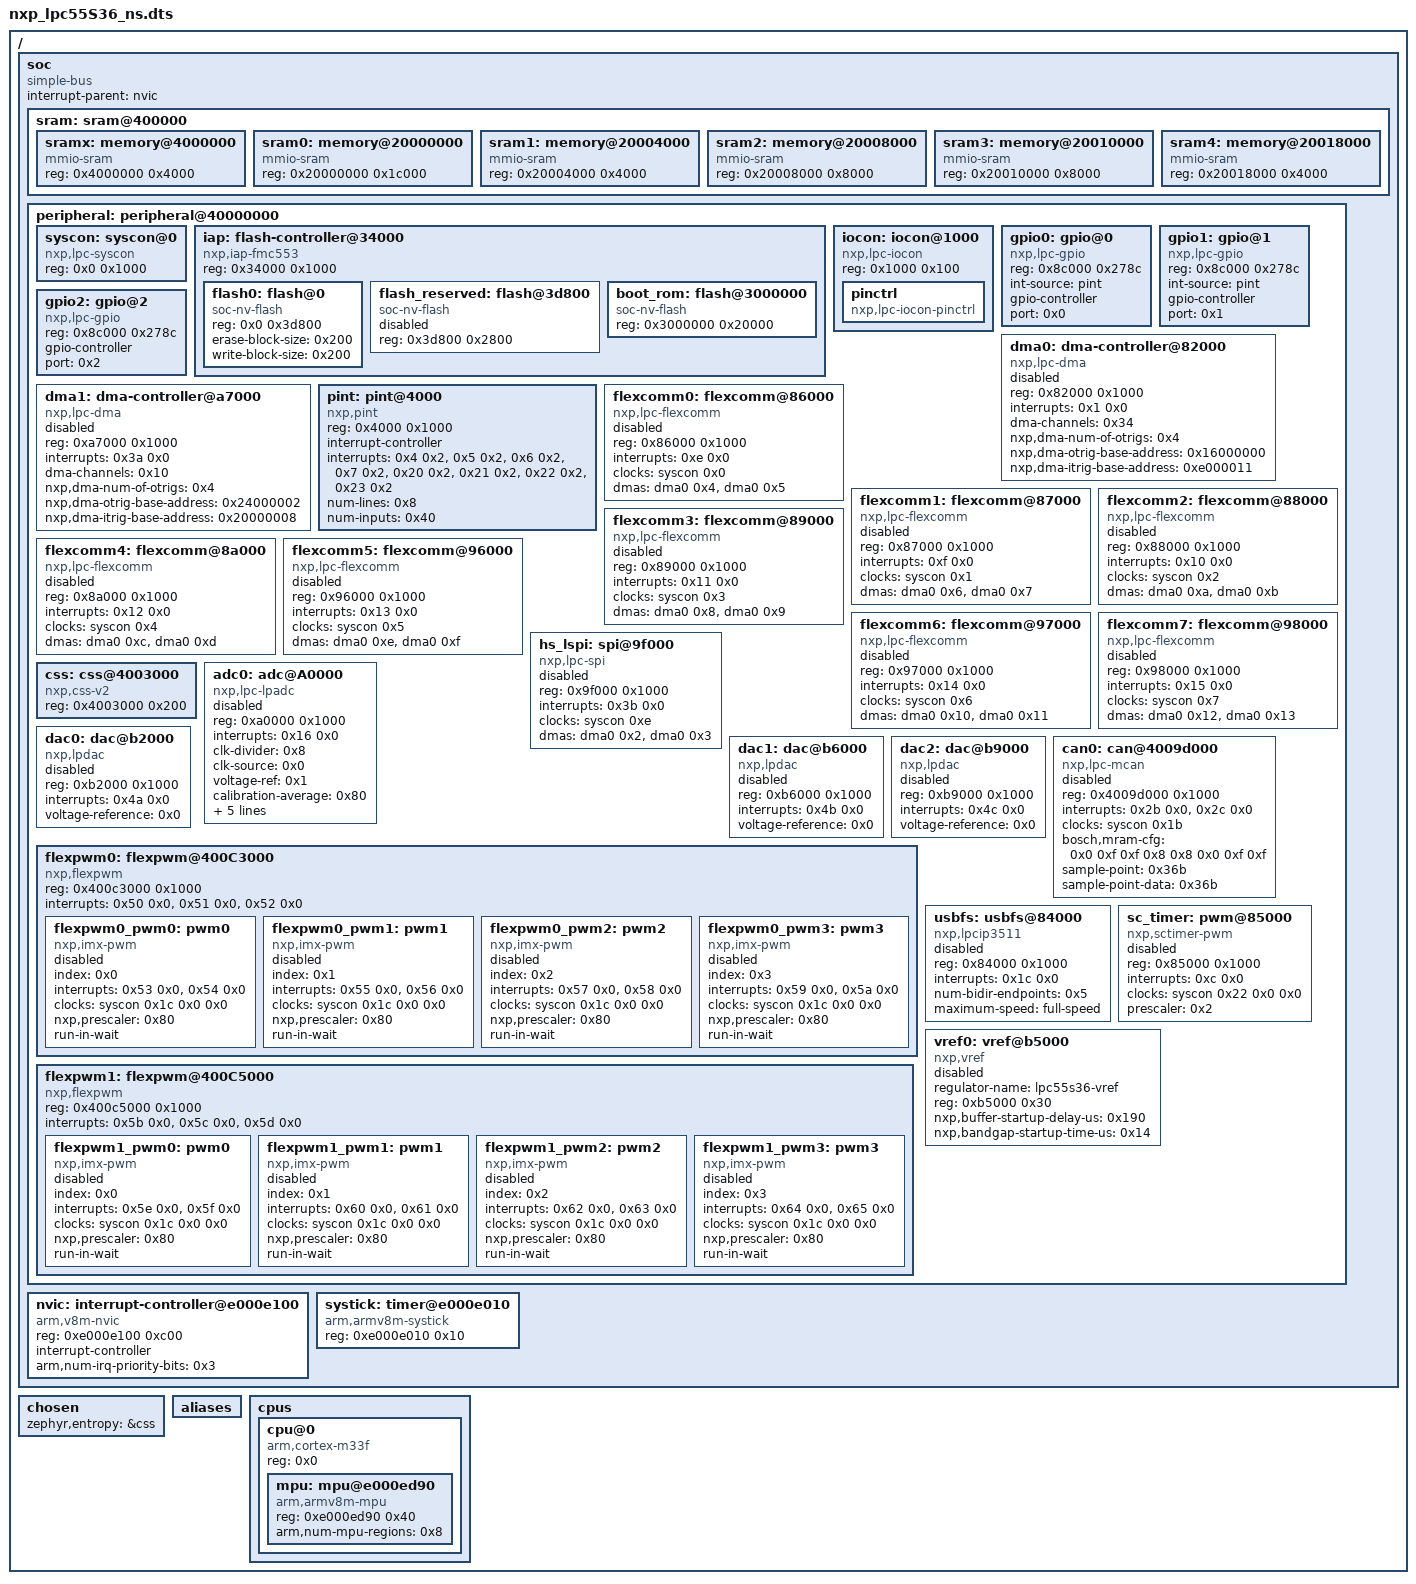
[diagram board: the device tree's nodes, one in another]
/dts-v1/;

/ {
	#address-cells = < 0x1 >;
	#size-cells = < 0x1 >;
	soc {
		#address-cells = < 0x1 >;
		#size-cells = < 0x1 >;
		compatible = "simple-bus";
		interrupt-parent = < &nvic >;
		ranges;
		sram: sram@400000 {
			ranges = < 0x4000000 0x4000000 0x20000000 >;
			#address-cells = < 0x1 >;
			#size-cells = < 0x1 >;
			sramx: memory@4000000 {
				compatible = "mmio-sram";
				reg = < 0x4000000 0x4000 >;
			};
			sram0: memory@20000000 {
				compatible = "mmio-sram";
				reg = < 0x20000000 0x1c000 >;
			};
			sram1: memory@20004000 {
				compatible = "mmio-sram";
				reg = < 0x20004000 0x4000 >;
			};
			sram2: memory@20008000 {
				compatible = "mmio-sram";
				reg = < 0x20008000 0x8000 >;
			};
			sram3: memory@20010000 {
				compatible = "mmio-sram";
				reg = < 0x20010000 0x8000 >;
			};
			sram4: memory@20018000 {
				compatible = "mmio-sram";
				reg = < 0x20018000 0x4000 >;
			};
		};
		peripheral: peripheral@40000000 {
			ranges = < 0x0 0x40000000 0x10000000 >;
			#address-cells = < 0x1 >;
			#size-cells = < 0x1 >;
			syscon: syscon@0 {
				compatible = "nxp,lpc-syscon";
				reg = < 0x0 0x1000 >;
				#clock-cells = < 0x1 >;
				phandle = < 0x2 >;
			};
			iap: flash-controller@34000 {
				compatible = "nxp,iap-fmc553";
				reg = < 0x34000 0x1000 >;
				#address-cells = < 0x1 >;
				#size-cells = < 0x1 >;
				status = "ok";
				flash0: flash@0 {
					compatible = "soc-nv-flash";
					reg = < 0x0 0x3d800 >;
					erase-block-size = < 0x200 >;
					write-block-size = < 0x200 >;
				};
				flash_reserved: flash@3d800 {
					compatible = "soc-nv-flash";
					reg = < 0x3d800 0x2800 >;
					status = "disabled";
				};
				boot_rom: flash@3000000 {
					compatible = "soc-nv-flash";
					reg = < 0x3000000 0x20000 >;
				};
			};
			iocon: iocon@1000 {
				compatible = "nxp,lpc-iocon";
				reg = < 0x1000 0x100 >;
				#address-cells = < 0x1 >;
				#size-cells = < 0x1 >;
				ranges = < 0x0 0x1000 0x100 >;
				pinctrl: pinctrl {
					compatible = "nxp,lpc-iocon-pinctrl";
				};
			};
			gpio0: gpio@0 {
				compatible = "nxp,lpc-gpio";
				reg = < 0x8c000 0x278c >;
				int-source = "pint";
				gpio-controller;
				#gpio-cells = < 0x2 >;
				port = < 0x0 >;
			};
			gpio1: gpio@1 {
				compatible = "nxp,lpc-gpio";
				reg = < 0x8c000 0x278c >;
				int-source = "pint";
				gpio-controller;
				#gpio-cells = < 0x2 >;
				port = < 0x1 >;
			};
			gpio2: gpio@2 {
				compatible = "nxp,lpc-gpio";
				reg = < 0x8c000 0x278c >;
				gpio-controller;
				#gpio-cells = < 0x2 >;
				port = < 0x2 >;
			};
			dma0: dma-controller@82000 {
				compatible = "nxp,lpc-dma";
				reg = < 0x82000 0x1000 >;
				interrupts = < 0x1 0x0 >;
				dma-channels = < 0x34 >;
				nxp,dma-num-of-otrigs = < 0x4 >;
				nxp,dma-otrig-base-address = < 0x16000000 >;
				nxp,dma-itrig-base-address = < 0xe000011 >;
				status = "disabled";
				#dma-cells = < 0x1 >;
				phandle = < 0x3 >;
			};
			dma1: dma-controller@a7000 {
				compatible = "nxp,lpc-dma";
				reg = < 0xa7000 0x1000 >;
				interrupts = < 0x3a 0x0 >;
				dma-channels = < 0x10 >;
				nxp,dma-num-of-otrigs = < 0x4 >;
				nxp,dma-otrig-base-address = < 0x24000002 >;
				nxp,dma-itrig-base-address = < 0x20000008 >;
				status = "disabled";
				#dma-cells = < 0x1 >;
			};
			pint: pint@4000 {
				compatible = "nxp,pint";
				reg = < 0x4000 0x1000 >;
				interrupt-controller;
				#interrupt-cells = < 0x1 >;
				#address-cells = < 0x0 >;
				interrupts = < 0x4 0x2 >, < 0x5 0x2 >, < 0x6 0x2 >, < 0x7 0x2 >, < 0x20 0x2 >, < 0x21 0x2 >, < 0x22 0x2 >, < 0x23 0x2 >;
				num-lines = < 0x8 >;
				num-inputs = < 0x40 >;
			};
			flexcomm0: flexcomm@86000 {
				compatible = "nxp,lpc-flexcomm";
				reg = < 0x86000 0x1000 >;
				interrupts = < 0xe 0x0 >;
				clocks = < &syscon 0x0 >;
				dmas = < &dma0 0x4 >, < &dma0 0x5 >;
				dma-names = "rx", "tx";
				status = "disabled";
			};
			flexcomm1: flexcomm@87000 {
				compatible = "nxp,lpc-flexcomm";
				reg = < 0x87000 0x1000 >;
				interrupts = < 0xf 0x0 >;
				clocks = < &syscon 0x1 >;
				dmas = < &dma0 0x6 >, < &dma0 0x7 >;
				dma-names = "rx", "tx";
				status = "disabled";
			};
			flexcomm2: flexcomm@88000 {
				compatible = "nxp,lpc-flexcomm";
				reg = < 0x88000 0x1000 >;
				interrupts = < 0x10 0x0 >;
				clocks = < &syscon 0x2 >;
				dmas = < &dma0 0xa >, < &dma0 0xb >;
				dma-names = "rx", "tx";
				status = "disabled";
			};
			flexcomm3: flexcomm@89000 {
				compatible = "nxp,lpc-flexcomm";
				reg = < 0x89000 0x1000 >;
				interrupts = < 0x11 0x0 >;
				clocks = < &syscon 0x3 >;
				dmas = < &dma0 0x8 >, < &dma0 0x9 >;
				dma-names = "rx", "tx";
				status = "disabled";
			};
			flexcomm4: flexcomm@8a000 {
				compatible = "nxp,lpc-flexcomm";
				reg = < 0x8a000 0x1000 >;
				interrupts = < 0x12 0x0 >;
				clocks = < &syscon 0x4 >;
				dmas = < &dma0 0xc >, < &dma0 0xd >;
				dma-names = "rx", "tx";
				status = "disabled";
			};
			flexcomm5: flexcomm@96000 {
				compatible = "nxp,lpc-flexcomm";
				reg = < 0x96000 0x1000 >;
				interrupts = < 0x13 0x0 >;
				clocks = < &syscon 0x5 >;
				dmas = < &dma0 0xe >, < &dma0 0xf >;
				dma-names = "rx", "tx";
				status = "disabled";
			};
			flexcomm6: flexcomm@97000 {
				compatible = "nxp,lpc-flexcomm";
				reg = < 0x97000 0x1000 >;
				interrupts = < 0x14 0x0 >;
				clocks = < &syscon 0x6 >;
				dmas = < &dma0 0x10 >, < &dma0 0x11 >;
				dma-names = "rx", "tx";
				status = "disabled";
			};
			flexcomm7: flexcomm@98000 {
				compatible = "nxp,lpc-flexcomm";
				reg = < 0x98000 0x1000 >;
				interrupts = < 0x15 0x0 >;
				clocks = < &syscon 0x7 >;
				dmas = < &dma0 0x12 >, < &dma0 0x13 >;
				dma-names = "rx", "tx";
				status = "disabled";
			};
			hs_lspi: spi@9f000 {
				compatible = "nxp,lpc-spi";
				reg = < 0x9f000 0x1000 >;
				interrupts = < 0x3b 0x0 >;
				clocks = < &syscon 0xe >;
				dmas = < &dma0 0x2 >, < &dma0 0x3 >;
				dma-names = "rx", "tx";
				status = "disabled";
				#address-cells = < 0x1 >;
				#size-cells = < 0x0 >;
			};
			css: css@4003000 {
				compatible = "nxp,css-v2";
				reg = < 0x4003000 0x200 >;
				status = "okay";
			};
			adc0: adc@A0000 {
				compatible = "nxp,lpc-lpadc";
				reg = < 0xa0000 0x1000 >;
				interrupts = < 0x16 0x0 >;
				status = "disabled";
				clk-divider = < 0x8 >;
				clk-source = < 0x0 >;
				voltage-ref = < 0x1 >;
				calibration-average = < 0x80 >;
				power-level = < 0x0 >;
				offset-value-a = < 0xa >;
				offset-value-b = < 0xa >;
				#io-channel-cells = < 0x1 >;
				dmas = < &dma0 0x15 >, < &dma0 0x16 >;
				dma-names = "adc0-dma0", "adc0-dma1";
				nxp,reference-supply = < &vref0 >;
			};
			dac0: dac@b2000 {
				compatible = "nxp,lpdac";
				reg = < 0xb2000 0x1000 >;
				interrupts = < 0x4a 0x0 >;
				status = "disabled";
				voltage-reference = < 0x0 >;
				#io-channel-cells = < 0x1 >;
			};
			dac1: dac@b6000 {
				compatible = "nxp,lpdac";
				reg = < 0xb6000 0x1000 >;
				interrupts = < 0x4b 0x0 >;
				status = "disabled";
				voltage-reference = < 0x0 >;
				#io-channel-cells = < 0x1 >;
			};
			dac2: dac@b9000 {
				compatible = "nxp,lpdac";
				reg = < 0xb9000 0x1000 >;
				interrupts = < 0x4c 0x0 >;
				status = "disabled";
				voltage-reference = < 0x0 >;
				#io-channel-cells = < 0x1 >;
			};
			can0: can@4009d000 {
				compatible = "nxp,lpc-mcan";
				reg = < 0x4009d000 0x1000 >;
				interrupts = < 0x2b 0x0 >, < 0x2c 0x0 >;
				clocks = < &syscon 0x1b >;
				bosch,mram-cfg = < 0x0 0xf 0xf 0x8 0x8 0x0 0xf 0xf >;
				sample-point = < 0x36b >;
				sample-point-data = < 0x36b >;
				status = "disabled";
			};
			flexpwm0: flexpwm@400C3000 {
				compatible = "nxp,flexpwm";
				reg = < 0x400c3000 0x1000 >;
				interrupt-names = "INPUT-CAPTURE", "FAULT", "RELOAD-ERROR";
				interrupts = < 0x50 0x0 >, < 0x51 0x0 >, < 0x52 0x0 >;
				flexpwm0_pwm0: pwm0 {
					compatible = "nxp,imx-pwm";
					index = < 0x0 >;
					interrupt-names = "COMPARE-SUB0", "RELOAD-SUB0";
					interrupts = < 0x53 0x0 >, < 0x54 0x0 >;
					#pwm-cells = < 0x3 >;
					clocks = < &syscon 0x1c 0x0 0x0 >;
					nxp,prescaler = < 0x80 >;
					status = "disabled";
					run-in-wait;
				};
				flexpwm0_pwm1: pwm1 {
					compatible = "nxp,imx-pwm";
					index = < 0x1 >;
					interrupt-names = "COMPARE-SUB1", "RELOAD-SUB1";
					interrupts = < 0x55 0x0 >, < 0x56 0x0 >;
					#pwm-cells = < 0x3 >;
					clocks = < &syscon 0x1c 0x0 0x0 >;
					nxp,prescaler = < 0x80 >;
					status = "disabled";
					run-in-wait;
				};
				flexpwm0_pwm2: pwm2 {
					compatible = "nxp,imx-pwm";
					index = < 0x2 >;
					interrupt-names = "COMPARE-SUB2", "RELOAD-SUB2";
					interrupts = < 0x57 0x0 >, < 0x58 0x0 >;
					#pwm-cells = < 0x3 >;
					clocks = < &syscon 0x1c 0x0 0x0 >;
					nxp,prescaler = < 0x80 >;
					status = "disabled";
					run-in-wait;
				};
				flexpwm0_pwm3: pwm3 {
					compatible = "nxp,imx-pwm";
					index = < 0x3 >;
					interrupt-names = "COMPARE-SUB3", "RELOAD-SUB3";
					interrupts = < 0x59 0x0 >, < 0x5a 0x0 >;
					#pwm-cells = < 0x3 >;
					clocks = < &syscon 0x1c 0x0 0x0 >;
					nxp,prescaler = < 0x80 >;
					status = "disabled";
					run-in-wait;
				};
			};
			flexpwm1: flexpwm@400C5000 {
				compatible = "nxp,flexpwm";
				reg = < 0x400c5000 0x1000 >;
				interrupt-names = "INPUT-CAPTURE", "FAULT", "RELOAD-ERROR";
				interrupts = < 0x5b 0x0 >, < 0x5c 0x0 >, < 0x5d 0x0 >;
				flexpwm1_pwm0: pwm0 {
					compatible = "nxp,imx-pwm";
					index = < 0x0 >;
					interrupt-names = "COMPARE-SUB0", "RELOAD-SUB0";
					interrupts = < 0x5e 0x0 >, < 0x5f 0x0 >;
					#pwm-cells = < 0x3 >;
					clocks = < &syscon 0x1c 0x0 0x0 >;
					nxp,prescaler = < 0x80 >;
					status = "disabled";
					run-in-wait;
				};
				flexpwm1_pwm1: pwm1 {
					compatible = "nxp,imx-pwm";
					index = < 0x1 >;
					interrupt-names = "COMPARE-SUB1", "RELOAD-SUB1";
					interrupts = < 0x60 0x0 >, < 0x61 0x0 >;
					#pwm-cells = < 0x3 >;
					clocks = < &syscon 0x1c 0x0 0x0 >;
					nxp,prescaler = < 0x80 >;
					status = "disabled";
					run-in-wait;
				};
				flexpwm1_pwm2: pwm2 {
					compatible = "nxp,imx-pwm";
					index = < 0x2 >;
					interrupt-names = "COMPARE-SUB2", "RELOAD-SUB2";
					interrupts = < 0x62 0x0 >, < 0x63 0x0 >;
					#pwm-cells = < 0x3 >;
					clocks = < &syscon 0x1c 0x0 0x0 >;
					nxp,prescaler = < 0x80 >;
					status = "disabled";
					run-in-wait;
				};
				flexpwm1_pwm3: pwm3 {
					compatible = "nxp,imx-pwm";
					index = < 0x3 >;
					interrupt-names = "COMPARE-SUB3", "RELOAD-SUB3";
					interrupts = < 0x64 0x0 >, < 0x65 0x0 >;
					#pwm-cells = < 0x3 >;
					clocks = < &syscon 0x1c 0x0 0x0 >;
					nxp,prescaler = < 0x80 >;
					status = "disabled";
					run-in-wait;
				};
			};
			usbfs: usbfs@84000 {
				compatible = "nxp,lpcip3511";
				reg = < 0x84000 0x1000 >;
				interrupts = < 0x1c 0x0 >;
				num-bidir-endpoints = < 0x5 >;
				maximum-speed = "full-speed";
				status = "disabled";
			};
			sc_timer: pwm@85000 {
				compatible = "nxp,sctimer-pwm";
				reg = < 0x85000 0x1000 >;
				interrupts = < 0xc 0x0 >;
				status = "disabled";
				clocks = < &syscon 0x22 0x0 0x0 >;
				prescaler = < 0x2 >;
				#pwm-cells = < 0x3 >;
			};
			vref0: vref@b5000 {
				compatible = "nxp,vref";
				regulator-name = "lpc55s36-vref";
				reg = < 0xb5000 0x30 >;
				status = "disabled";
				nxp,buffer-startup-delay-us = < 0x190 >;
				nxp,bandgap-startup-time-us = < 0x14 >;
				phandle = < 0x4 >;
			};
		};
		nvic: interrupt-controller@e000e100 {
			#address-cells = < 0x1 >;
			compatible = "arm,v8m-nvic";
			reg = < 0xe000e100 0xc00 >;
			interrupt-controller;
			#interrupt-cells = < 0x2 >;
			arm,num-irq-priority-bits = < 0x3 >;
			phandle = < 0x1 >;
		};
		systick: timer@e000e010 {
			compatible = "arm,armv8m-systick";
			reg = < 0xe000e010 0x10 >;
		};
	};
	chosen {
		zephyr,entropy = &css;
	};
	aliases {
	};
	cpus {
		#address-cells = < 0x1 >;
		#size-cells = < 0x0 >;
		cpu@0 {
			compatible = "arm,cortex-m33f";
			reg = < 0x0 >;
			#address-cells = < 0x1 >;
			#size-cells = < 0x1 >;
			mpu: mpu@e000ed90 {
				compatible = "arm,armv8m-mpu";
				reg = < 0xe000ed90 0x40 >;
				arm,num-mpu-regions = < 0x8 >;
			};
		};
	};
};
